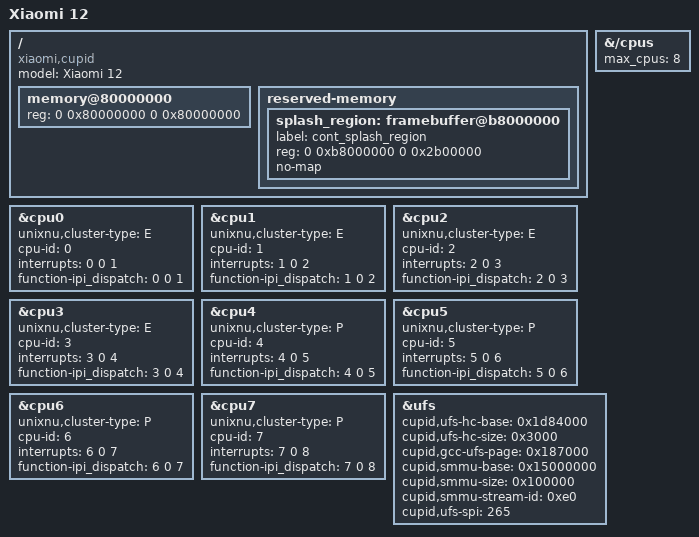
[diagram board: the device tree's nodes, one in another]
// SPDX-License-Identifier: BSD-3-Clause
// Xiaomi 12 (cupid), Qualcomm SM8450 (waipio).
//
// Memory handoff and splash geometry follow the vendor device trees
// (LineageOS android_kernel_xiaomi_sm8450-devicetrees):
//   - qcom/waipio.dtsi:            qcom,msm-id = <457 0x10000>
//   - qcom/display/display/waipio-sde-display.dtsi:
//                                  cont_splash_region 0xb8000000 + 0x2b00000
//   - qcom/cupid-sm8450.dtsi:      panel 1080x2400, FTS SPI touch
/dts-v1/;
/include/ "sm8450.dtsi"

/ {
    model = "Xiaomi 12";
    compatible = "xiaomi,cupid", "qcom,sm8450";

    // Nominal handoff range, as sheng. DarwinBoot owns the contiguous window
    // selected by [payload.adt] owned_memory_size from the UEFI memory map.
    // REQUIRED: replace 2 GiB with the measured cupid window once dumped.
    memory@80000000 {
        device_type = "memory";
        reg = <0 0x80000000 0 0x80000000>;
    };

    reserved-memory {
        #address-cells = <2>;
        #size-cells = <2>;
        ranges;
        // Stock continuous-splash framebuffer for 1080x2400.
        splash_region: framebuffer@b8000000 {
            label = "cont_splash_region";
            reg = <0 0xb8000000 0 0x2b00000>;
            no-map;
        };
    };
};

// cpu0-3 Cortex-A510 (E); cpu4-6 Cortex-A710 and cpu7 Cortex-X2 (P).
// MPIDR Affinity1 0x000-0x700, matching mainline sm8450.dtsi.
//
// AppleARMCPU::_validateConfiguration() reads the ADT, and the ADT handed to XNU
// is generated from *this* tree (device:dts/cupid.dts + soc:dts/sm8450.dtsi),
// not from build/cupid/cupid.dtb — that one only feeds the boot.img FDT. Without
// Apple's CPU property contract the kernel panics with
// "CPU configuration in device tree is invalid" at AppleARMCPU.cpp:111:
//
//   /cpus      max_cpus (4 bytes, non-zero) >= the number of cpu children
//   each cpu   cpu-id (4 bytes) == interrupts[0]; interrupts[2] == cpu-id + 1
//              function-ipi_dispatch (3 cells) == interrupts
//
// sm8450.dtsi gives each cpu only a 2-cell `reg` (8 bytes, a length Apple
// rejects), so cpu-id has to be supplied explicitly.
&{/cpus} {
    max_cpus = <8>;
};

&cpu0 { unixnu,cluster-type = "E"; cpu-id = <0>; interrupts = <0 0 1>; function-ipi_dispatch = <0 0 1>; };
&cpu1 { unixnu,cluster-type = "E"; cpu-id = <1>; interrupts = <1 0 2>; function-ipi_dispatch = <1 0 2>; };
&cpu2 { unixnu,cluster-type = "E"; cpu-id = <2>; interrupts = <2 0 3>; function-ipi_dispatch = <2 0 3>; };
&cpu3 { unixnu,cluster-type = "E"; cpu-id = <3>; interrupts = <3 0 4>; function-ipi_dispatch = <3 0 4>; };
&cpu4 { unixnu,cluster-type = "P"; cpu-id = <4>; interrupts = <4 0 5>; function-ipi_dispatch = <4 0 5>; };
&cpu5 { unixnu,cluster-type = "P"; cpu-id = <5>; interrupts = <5 0 6>; function-ipi_dispatch = <5 0 6>; };
&cpu6 { unixnu,cluster-type = "P"; cpu-id = <6>; interrupts = <6 0 7>; function-ipi_dispatch = <6 0 7>; };
&cpu7 { unixnu,cluster-type = "P"; cpu-id = <7>; interrupts = <7 0 8>; function-ipi_dispatch = <7 0 8>; };

// No storage, GPU or input component is selected for stage 0, so the nodes
// stay disabled. Enabling them without a matching driver only publishes
// resources no kext will claim.

// UFS bring-up. Every number is a board fact, not a copy from SM8550:
// upstream qcom/waipio (sm8450.dtsi) gives hc 0x1d84000 size 0x3000, SPI 265,
// apps_smmu 0x15000000 size 0x100000 and iommus = <&apps_smmu 0xe0 0x0>;
// gcc-sm8450.c puts every UFS branch in the 0x87000 window of GCC (0x187000).
// The transport takes over the controller the bootloader already started, so
// the QMP PHY (0x1d87000) is not driven from here yet.
&ufs {
    status = "okay";
    cupid,ufs-hc-base = /bits/ 64 <0x1d84000>;
    cupid,ufs-hc-size = /bits/ 64 <0x3000>;
    cupid,gcc-ufs-page = /bits/ 64 <0x187000>;
    cupid,smmu-base = /bits/ 64 <0x15000000>;
    cupid,smmu-size = /bits/ 64 <0x100000>;
    cupid,smmu-stream-id = <0xe0>;
    cupid,ufs-spi = <265>;
};
